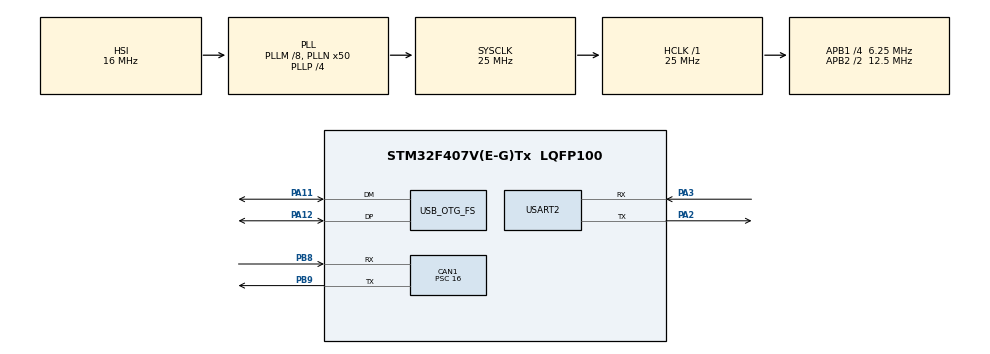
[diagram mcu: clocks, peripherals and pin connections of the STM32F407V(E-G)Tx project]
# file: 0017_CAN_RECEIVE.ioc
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CAN1.BS1=CAN_BS1_2TQ
CAN1.BS2=CAN_BS2_2TQ
CAN1.CalculateBaudRate=78125
CAN1.CalculateTimeBit=12800
CAN1.CalculateTimeQuantum=2560.0
CAN1.Prescaler=16
Mcu.Family=STM32F4
Mcu.Name=STM32F407V(E-G)Tx
Mcu.Package=LQFP100
NVIC.OTG_FS_IRQn=true\:0\:0\:false\:false\:true\:false\:true\:true
NVIC.PriorityGroup=NVIC_PRIORITYGROUP_0
PA11.Mode=Device_Only
PA11.Signal=USB_OTG_FS_DM
PA12.Mode=Device_Only
PA12.Signal=USB_OTG_FS_DP
PA2.Mode=Asynchronous
PA2.Signal=USART2_TX
PA3.Mode=Asynchronous
PA3.Signal=USART2_RX
PB8.Mode=CAN_Activate
PB8.Signal=CAN1_RX
PB9.Mode=CAN_Activate
PB9.Signal=CAN1_TX
ProjectManager.HeapSize=0x200
ProjectManager.StackSize=0x400
ProjectManager.TargetToolchain=STM32CubeIDE
RCC.48MHZClocksFreq_Value=14285714.285714285
RCC.AHBFreq_Value=25000000
RCC.APB1CLKDivider=RCC_HCLK_DIV4
RCC.APB1Freq_Value=6250000
RCC.APB1TimFreq_Value=12500000
RCC.APB2CLKDivider=RCC_HCLK_DIV2
RCC.APB2Freq_Value=12500000
RCC.APB2TimFreq_Value=25000000
RCC.CortexFreq_Value=25000000
RCC.HCLKFreq_Value=25000000
RCC.HSE_VALUE=8000000
RCC.HSI_VALUE=16000000
RCC.LSE_VALUE=32768
RCC.PLLM=8
RCC.PLLN=50
RCC.PLLP=RCC_PLLP_DIV4
RCC.PLLQ=7
RCC.PLLSourceVirtualString=RCC_PLLSOURCE_HSI
RCC.SYSCLKFreq_VALUE=25000000
RCC.SYSCLKSource=RCC_SYSCLKSOURCE_PLLCLK
RCC.VCOOutputFreq_Value=100000000
USART2.VirtualMode=VM_ASYNC
USB_DEVICE.CLASS_NAME_FS=CDC
USB_DEVICE.VirtualMode-CDC_FS=Cdc
USB_DEVICE.VirtualModeFS=Cdc_FS
USB_OTG_FS.VirtualMode=Device_Only
VP_USB_DEVICE_VS_USB_DEVICE_CDC_FS.Mode=CDC_FS
board=STM32F407G-DISC1

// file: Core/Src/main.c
/* USER CODE BEGIN Header */
/**
  ******************************************************************************
  * @file           : main.c
  * @brief          : Main program body
  ******************************************************************************
  * @attention
  *
  * Copyright (c) 2026 STMicroelectronics.
  * All rights reserved.
  *
  * This software is licensed under terms that can be found in the LICENSE file
  * in the root directory of this software component.
  * If no LICENSE file comes with this software, it is provided AS-IS.
  *
  ******************************************************************************
  */
/* USER CODE END Header */
#include "main.h"
#include "usb_device.h"

CAN_HandleTypeDef hcan1;

UART_HandleTypeDef huart2;

/* USER CODE BEGIN PV */
uint8_t msg[50] = "Hello world! \r\n";

/* USER CODE END PV */

void SystemClock_Config(void);
static void MX_GPIO_Init(void);
static void MX_CAN1_Init(void);
static void MX_USART2_UART_Init(void);

int main(void)
{

  /* MCU Configuration--------------------------------------------------------*/

  /* Reset of all peripherals, Initializes the Flash interface and the Systick. */
  HAL_Init();

  /* Configure the system clock */
  SystemClock_Config();

  /* Initialize all configured peripherals */
  MX_GPIO_Init();
  MX_CAN1_Init();
  MX_USART2_UART_Init();
  MX_USB_DEVICE_Init();

  /* Infinite loop */
  while (1)
  {

    /* USER CODE BEGIN 3 */
	  CDC_Transmit_FS(msg, sizeof(msg));
  }
  /* USER CODE END 3 */
}

void SystemClock_Config(void)
{
  RCC_OscInitTypeDef RCC_OscInitStruct = {0};
  RCC_ClkInitTypeDef RCC_ClkInitStruct = {0};

  /** Configure the main internal regulator output voltage
  */
  __HAL_RCC_PWR_CLK_ENABLE();
  __HAL_PWR_VOLTAGESCALING_CONFIG(PWR_REGULATOR_VOLTAGE_SCALE1);

  /** Initializes the RCC Oscillators according to the specified parameters
  * in the RCC_OscInitTypeDef structure.
  */
  RCC_OscInitStruct.OscillatorType = RCC_OSCILLATORTYPE_HSI;
  RCC_OscInitStruct.HSIState = RCC_HSI_ON;
  RCC_OscInitStruct.HSICalibrationValue = RCC_HSICALIBRATION_DEFAULT;
  RCC_OscInitStruct.PLL.PLLState = RCC_PLL_ON;
  RCC_OscInitStruct.PLL.PLLSource = RCC_PLLSOURCE_HSI;
  RCC_OscInitStruct.PLL.PLLM = 8;
  RCC_OscInitStruct.PLL.PLLN = 50;
  RCC_OscInitStruct.PLL.PLLP = RCC_PLLP_DIV4;
  RCC_OscInitStruct.PLL.PLLQ = 7;
  if (HAL_RCC_OscConfig(&RCC_OscInitStruct) != HAL_OK)
  {
    Error_Handler();
  }

  /** Initializes the CPU, AHB and APB buses clocks
  */
  RCC_ClkInitStruct.ClockType = RCC_CLOCKTYPE_HCLK|RCC_CLOCKTYPE_SYSCLK
                              |RCC_CLOCKTYPE_PCLK1|RCC_CLOCKTYPE_PCLK2;
  RCC_ClkInitStruct.SYSCLKSource = RCC_SYSCLKSOURCE_PLLCLK;
  RCC_ClkInitStruct.AHBCLKDivider = RCC_SYSCLK_DIV1;
  RCC_ClkInitStruct.APB1CLKDivider = RCC_HCLK_DIV4;
  RCC_ClkInitStruct.APB2CLKDivider = RCC_HCLK_DIV2;

  if (HAL_RCC_ClockConfig(&RCC_ClkInitStruct, FLASH_LATENCY_0) != HAL_OK)
  {
    Error_Handler();
  }
}

static void MX_CAN1_Init(void)
{

  hcan1.Instance = CAN1;
  hcan1.Init.Prescaler = 16;
  hcan1.Init.Mode = CAN_MODE_NORMAL;
  hcan1.Init.SyncJumpWidth = CAN_SJW_1TQ;
  hcan1.Init.TimeSeg1 = CAN_BS1_2TQ;
  hcan1.Init.TimeSeg2 = CAN_BS2_2TQ;
  hcan1.Init.TimeTriggeredMode = DISABLE;
  hcan1.Init.AutoBusOff = DISABLE;
  hcan1.Init.AutoWakeUp = DISABLE;
  hcan1.Init.AutoRetransmission = DISABLE;
  hcan1.Init.ReceiveFifoLocked = DISABLE;
  hcan1.Init.TransmitFifoPriority = DISABLE;
  if (HAL_CAN_Init(&hcan1) != HAL_OK)
  {
    Error_Handler();
  }

}

static void MX_USART2_UART_Init(void)
{

  huart2.Instance = USART2;
  huart2.Init.BaudRate = 115200;
  huart2.Init.WordLength = UART_WORDLENGTH_8B;
  huart2.Init.StopBits = UART_STOPBITS_1;
  huart2.Init.Parity = UART_PARITY_NONE;
  huart2.Init.Mode = UART_MODE_TX_RX;
  huart2.Init.HwFlowCtl = UART_HWCONTROL_NONE;
  huart2.Init.OverSampling = UART_OVERSAMPLING_16;
  if (HAL_UART_Init(&huart2) != HAL_OK)
  {
    Error_Handler();
  }

}

static void MX_GPIO_Init(void)
{

  /* GPIO Ports Clock Enable */
  __HAL_RCC_GPIOA_CLK_ENABLE();
  __HAL_RCC_GPIOB_CLK_ENABLE();

}

void Error_Handler(void)
{
  __disable_irq();
  while (1)
  {
  }
}
